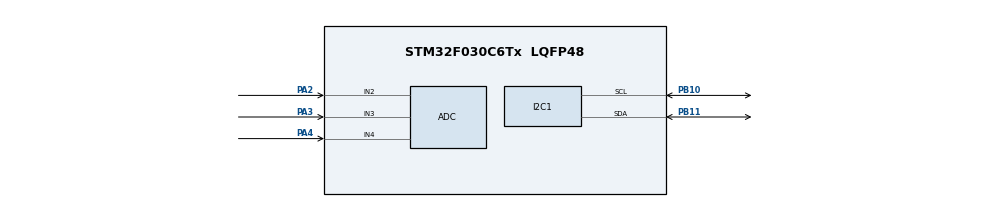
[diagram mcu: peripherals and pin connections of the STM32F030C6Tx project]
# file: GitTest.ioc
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FREERTOS.Tasks01=defaultTask,0,96,StartDefaultTask,Default,NULL,Dynamic,NULL,NULL
Mcu.Family=STM32F0
Mcu.Name=STM32F030C6Tx
Mcu.Package=LQFP48
PA2.Mode=IN2
PA2.Signal=ADC_IN2
PA3.Mode=IN3
PA3.Signal=ADC_IN3
PA4.Mode=IN4
PA4.Signal=ADC_IN4
PB10.Mode=I2C
PB10.Signal=I2C1_SCL
PB11.Mode=I2C
PB11.Signal=I2C1_SDA
ProjectManager.HeapSize=0x200
ProjectManager.StackSize=0x400
ProjectManager.TargetToolchain=MDK-ARM V5.27
VP_FATFS_VS_Generic.Mode=User_defined
VP_FREERTOS_VS_CMSIS_V1.Mode=CMSIS_V1
board=custom

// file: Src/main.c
/* USER CODE BEGIN Header */
/**
  ******************************************************************************
  * @file           : main.c
  * @brief          : Main program body
  ******************************************************************************
  * @attention
  *
  * <h2><center>&copy; Copyright (c) 2020 STMicroelectronics.
  * All rights reserved.</center></h2>
  *
  * This software component is licensed by ST under Ultimate Liberty license
  * SLA0044, the "License"; You may not use this file except in compliance with
  * the License. You may obtain a copy of the License at:
  *                             www.st.com/SLA0044
  *
  ******************************************************************************
  */
/* USER CODE END Header */

//my test file

#include "main.h"
#include "cmsis_os.h"
#include "fatfs.h"

//new new test

ADC_HandleTypeDef hadc;

I2C_HandleTypeDef hi2c1;

osThreadId defaultTaskHandle;

void SystemClock_Config(void);
static void MX_GPIO_Init(void);
static void MX_ADC_Init(void);
static void MX_I2C1_Init(void);
void StartDefaultTask(void const * argument);

int main(void)
{

  /* MCU Configuration--------------------------------------------------------*/

  /* Reset of all peripherals, Initializes the Flash interface and the Systick. */
  HAL_Init();

  /* Configure the system clock */
  SystemClock_Config();

  /* Initialize all configured peripherals */
  MX_GPIO_Init();
  MX_ADC_Init();
  MX_I2C1_Init();
  MX_FATFS_Init();
  /* USER CODE BEGIN 2 */

	void main_3(void);

  /* USER CODE END 2 */

  //void change4();

  /* Create the thread(s) */
  /* definition and creation of defaultTask */
  osThreadDef(defaultTask, StartDefaultTask, osPriorityNormal, 0, 96);
  defaultTaskHandle = osThreadCreate(osThread(defaultTask), NULL);

  /* Start scheduler */
  osKernelStart();

  /* We should never get here as control is now taken by the scheduler */
  /* Infinite loop */
  while (1)
  {

  }
}

void SystemClock_Config(void)
{
  RCC_OscInitTypeDef RCC_OscInitStruct = {0};
  RCC_ClkInitTypeDef RCC_ClkInitStruct = {0};
  RCC_PeriphCLKInitTypeDef PeriphClkInit = {0};

  /** Initializes the CPU, AHB and APB busses clocks
  */
  RCC_OscInitStruct.OscillatorType = RCC_OSCILLATORTYPE_HSI|RCC_OSCILLATORTYPE_HSI14;
  RCC_OscInitStruct.HSIState = RCC_HSI_ON;
  RCC_OscInitStruct.HSI14State = RCC_HSI14_ON;
  RCC_OscInitStruct.HSICalibrationValue = RCC_HSICALIBRATION_DEFAULT;
  RCC_OscInitStruct.HSI14CalibrationValue = 16;
  RCC_OscInitStruct.PLL.PLLState = RCC_PLL_NONE;
  if (HAL_RCC_OscConfig(&RCC_OscInitStruct) != HAL_OK)
  {
    Error_Handler();
  }
  /** Initializes the CPU, AHB and APB busses clocks
  */
  RCC_ClkInitStruct.ClockType = RCC_CLOCKTYPE_HCLK|RCC_CLOCKTYPE_SYSCLK
                              |RCC_CLOCKTYPE_PCLK1;
  RCC_ClkInitStruct.SYSCLKSource = RCC_SYSCLKSOURCE_HSI;
  RCC_ClkInitStruct.AHBCLKDivider = RCC_SYSCLK_DIV1;
  RCC_ClkInitStruct.APB1CLKDivider = RCC_HCLK_DIV1;

  if (HAL_RCC_ClockConfig(&RCC_ClkInitStruct, FLASH_LATENCY_0) != HAL_OK)
  {
    Error_Handler();
  }
  PeriphClkInit.PeriphClockSelection = RCC_PERIPHCLK_I2C1;
  PeriphClkInit.I2c1ClockSelection = RCC_I2C1CLKSOURCE_HSI;
  if (HAL_RCCEx_PeriphCLKConfig(&PeriphClkInit) != HAL_OK)
  {
    Error_Handler();
  }
}

static void MX_ADC_Init(void)
{

  ADC_ChannelConfTypeDef sConfig = {0};

  /** Configure the global features of the ADC (Clock, Resolution, Data Alignment and number of conversion)
  */
  hadc.Instance = ADC1;
  hadc.Init.ClockPrescaler = ADC_CLOCK_ASYNC_DIV1;
  hadc.Init.Resolution = ADC_RESOLUTION_12B;
  hadc.Init.DataAlign = ADC_DATAALIGN_RIGHT;
  hadc.Init.ScanConvMode = ADC_SCAN_DIRECTION_FORWARD;
  hadc.Init.EOCSelection = ADC_EOC_SINGLE_CONV;
  hadc.Init.LowPowerAutoWait = DISABLE;
  hadc.Init.LowPowerAutoPowerOff = DISABLE;
  hadc.Init.ContinuousConvMode = DISABLE;
  hadc.Init.DiscontinuousConvMode = DISABLE;
  hadc.Init.ExternalTrigConv = ADC_SOFTWARE_START;
  hadc.Init.ExternalTrigConvEdge = ADC_EXTERNALTRIGCONVEDGE_NONE;
  hadc.Init.DMAContinuousRequests = DISABLE;
  hadc.Init.Overrun = ADC_OVR_DATA_PRESERVED;
  if (HAL_ADC_Init(&hadc) != HAL_OK)
  {
    Error_Handler();
  }
  /** Configure for the selected ADC regular channel to be converted.
  */
  sConfig.Channel = ADC_CHANNEL_2;
  sConfig.Rank = ADC_RANK_CHANNEL_NUMBER;
  sConfig.SamplingTime = ADC_SAMPLETIME_1CYCLE_5;
  if (HAL_ADC_ConfigChannel(&hadc, &sConfig) != HAL_OK)
  {
    Error_Handler();
  }
  /** Configure for the selected ADC regular channel to be converted.
  */
  sConfig.Channel = ADC_CHANNEL_3;
  if (HAL_ADC_ConfigChannel(&hadc, &sConfig) != HAL_OK)
  {
    Error_Handler();
  }
  /** Configure for the selected ADC regular channel to be converted.
  */
  sConfig.Channel = ADC_CHANNEL_4;
  if (HAL_ADC_ConfigChannel(&hadc, &sConfig) != HAL_OK)
  {
    Error_Handler();
  }

}

static void MX_I2C1_Init(void)
{

  hi2c1.Instance = I2C1;
  hi2c1.Init.Timing = 0x2000090E;
  hi2c1.Init.OwnAddress1 = 0;
  hi2c1.Init.AddressingMode = I2C_ADDRESSINGMODE_7BIT;
  hi2c1.Init.DualAddressMode = I2C_DUALADDRESS_DISABLE;
  hi2c1.Init.OwnAddress2 = 0;
  hi2c1.Init.OwnAddress2Masks = I2C_OA2_NOMASK;
  hi2c1.Init.GeneralCallMode = I2C_GENERALCALL_DISABLE;
  hi2c1.Init.NoStretchMode = I2C_NOSTRETCH_DISABLE;
  if (HAL_I2C_Init(&hi2c1) != HAL_OK)
  {
    Error_Handler();
  }
  /** Configure Analogue filter
  */
  if (HAL_I2CEx_ConfigAnalogFilter(&hi2c1, I2C_ANALOGFILTER_ENABLE) != HAL_OK)
  {
    Error_Handler();
  }
  /** Configure Digital filter
  */
  if (HAL_I2CEx_ConfigDigitalFilter(&hi2c1, 0) != HAL_OK)
  {
    Error_Handler();
  }

}

static void MX_GPIO_Init(void)
{

  /* GPIO Ports Clock Enable */
  __HAL_RCC_GPIOA_CLK_ENABLE();
  __HAL_RCC_GPIOB_CLK_ENABLE();

}

void StartDefaultTask(void const * argument)
{
  for(;;)
  {
    osDelay(1);
  }
}

void Error_Handler(void)
{
}

/************************ (C) COPYRIGHT STMicroelectronics *****END OF FILE****/
